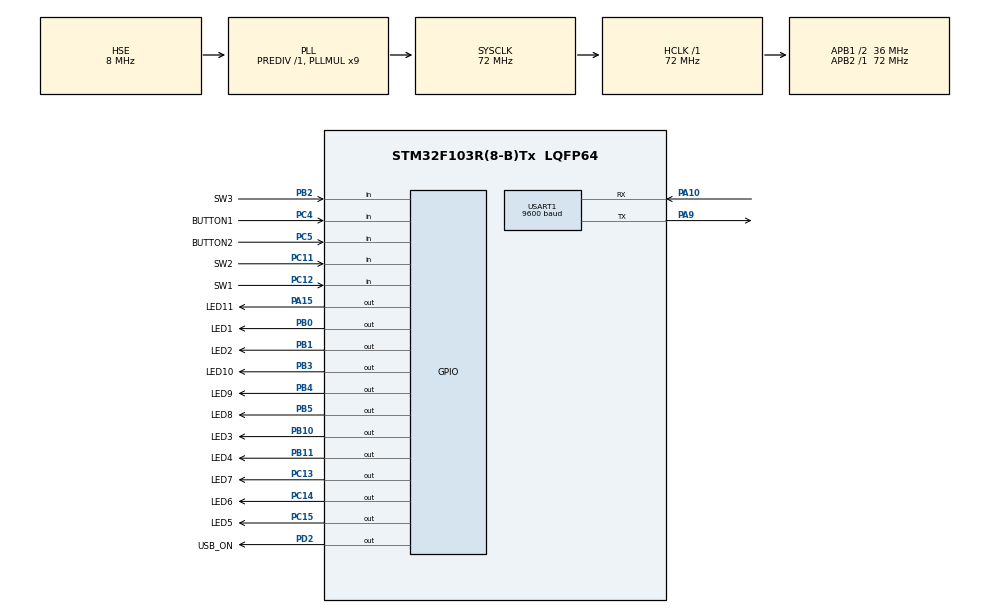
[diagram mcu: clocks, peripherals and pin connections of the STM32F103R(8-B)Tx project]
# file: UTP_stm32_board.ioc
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Mcu.Family=STM32F1
Mcu.Name=STM32F103R(8-B)Tx
Mcu.Package=LQFP64
NVIC.PriorityGroup=NVIC_PRIORITYGROUP_4
NVIC.USART1_IRQn=true\:0\:0\:false\:false\:true\:true
PA10.Mode=Asynchronous
PA10.Signal=USART1_RX
PA13.Mode=Serial_Wire
PA13.Signal=SYS_JTMS-SWDIO
PA14.Mode=Serial_Wire
PA14.Signal=SYS_JTCK-SWCLK
PA15.GPIO_Label=LED11
PA15.PinState=GPIO_PIN_SET
PA15.Signal=GPIO_Output
PA9.Mode=Asynchronous
PA9.Signal=USART1_TX
PB0.GPIO_Label=LED1
PB0.PinState=GPIO_PIN_SET
PB0.Signal=GPIO_Output
PB1.GPIO_Label=LED2
PB1.PinState=GPIO_PIN_SET
PB1.Signal=GPIO_Output
PB10.GPIO_Label=LED3
PB10.PinState=GPIO_PIN_SET
PB10.Signal=GPIO_Output
PB11.GPIO_Label=LED4
PB11.PinState=GPIO_PIN_SET
PB11.Signal=GPIO_Output
PB2.GPIO_Label=SW3
PB2.GPIO_PuPd=GPIO_PULLUP
PB2.Signal=GPIO_Input
PB3.GPIO_Label=LED10
PB3.PinState=GPIO_PIN_SET
PB3.Signal=GPIO_Output
PB4.GPIO_Label=LED9
PB4.PinState=GPIO_PIN_SET
PB4.Signal=GPIO_Output
PB5.GPIO_Label=LED8
PB5.PinState=GPIO_PIN_SET
PB5.Signal=GPIO_Output
PC11.GPIO_Label=SW2
PC11.GPIO_PuPd=GPIO_PULLUP
PC11.Signal=GPIO_Input
PC12.GPIO_Label=SW1
PC12.GPIO_PuPd=GPIO_PULLUP
PC12.Signal=GPIO_Input
PC13-TAMPER-RTC.GPIO_Label=LED7
PC13-TAMPER-RTC.PinState=GPIO_PIN_SET
PC13-TAMPER-RTC.Signal=GPIO_Output
PC14-OSC32_IN.GPIO_Label=LED6
PC14-OSC32_IN.PinState=GPIO_PIN_SET
PC14-OSC32_IN.Signal=GPIO_Output
PC15-OSC32_OUT.GPIO_Label=LED5
PC15-OSC32_OUT.PinState=GPIO_PIN_SET
PC15-OSC32_OUT.Signal=GPIO_Output
PC4.GPIO_Label=BUTTON1
PC4.GPIO_PuPd=GPIO_PULLUP
PC4.Signal=GPIO_Input
PC5.GPIO_Label=BUTTON2
PC5.GPIO_PuPd=GPIO_PULLUP
PC5.Signal=GPIO_Input
PD0-OSC_IN.Mode=HSE-External-Oscillator
PD0-OSC_IN.Signal=RCC_OSC_IN
PD1-OSC_OUT.Mode=HSE-External-Oscillator
PD1-OSC_OUT.Signal=RCC_OSC_OUT
PD2.GPIO_Label=USB_ON
PD2.PinState=GPIO_PIN_SET
PD2.Signal=GPIO_Output
ProjectManager.HeapSize=0x200
ProjectManager.StackSize=0x400
ProjectManager.TargetToolchain=TrueSTUDIO
RCC.ADCPresc=RCC_ADCPCLK2_DIV6
RCC.AHBFreq_Value=72000000
RCC.APB1CLKDivider=RCC_HCLK_DIV2
RCC.APB1Freq_Value=36000000
RCC.APB1TimFreq_Value=72000000
RCC.APB2Freq_Value=72000000
RCC.APB2TimFreq_Value=72000000
RCC.HCLKFreq_Value=72000000
RCC.PLLMUL=RCC_PLL_MUL9
RCC.PLLSourceVirtual=RCC_PLLSOURCE_HSE
RCC.SYSCLKFreq_VALUE=72000000
RCC.SYSCLKSource=RCC_SYSCLKSOURCE_PLLCLK
RCC.USBFreq_Value=48000000
RCC.USBPrescaler=RCC_USBCLKSOURCE_PLL_DIV1_5
USART1.BaudRate=9600
USART1.Parity=PARITY_ODD
USART1.StopBits=STOPBITS_2
USART1.VirtualMode=VM_ASYNC
board=UTP_stm32_board

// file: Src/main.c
/**
  ******************************************************************************
  * File Name          : main.c
  * Description        : Main program body
  ******************************************************************************
  ** This notice applies to any and all portions of this file
  * that are not between comment pairs USER CODE BEGIN and
  * USER CODE END. Other portions of this file, whether
  * inserted by the user or by software development tools
  * are owned by their respective copyright owners.
  *
  * COPYRIGHT(c) 2017 STMicroelectronics
  *
  * Redistribution and use in source and binary forms, with or without modification,
  * are permitted provided that the following conditions are met:
  *   1. Redistributions of source code must retain the above copyright notice,
  *      this list of conditions and the following disclaimer.
  *   2. Redistributions in binary form must reproduce the above copyright notice,
  *      this list of conditions and the following disclaimer in the documentation
  *      and/or other materials provided with the distribution.
  *   3. Neither the name of STMicroelectronics nor the names of its contributors
  *      may be used to endorse or promote products derived from this software
  *      without specific prior written permission.
  *
  * THIS SOFTWARE IS PROVIDED BY THE COPYRIGHT HOLDERS AND CONTRIBUTORS "AS IS"
  * AND ANY EXPRESS OR IMPLIED WARRANTIES, INCLUDING, BUT NOT LIMITED TO, THE
  * IMPLIED WARRANTIES OF MERCHANTABILITY AND FITNESS FOR A PARTICULAR PURPOSE ARE
  * DISCLAIMED. IN NO EVENT SHALL THE COPYRIGHT HOLDER OR CONTRIBUTORS BE LIABLE
  * FOR ANY DIRECT, INDIRECT, INCIDENTAL, SPECIAL, EXEMPLARY, OR CONSEQUENTIAL
  * DAMAGES (INCLUDING, BUT NOT LIMITED TO, PROCUREMENT OF SUBSTITUTE GOODS OR
  * SERVICES; LOSS OF USE, DATA, OR PROFITS; OR BUSINESS INTERRUPTION) HOWEVER
  * CAUSED AND ON ANY THEORY OF LIABILITY, WHETHER IN CONTRACT, STRICT LIABILITY,
  * OR TORT (INCLUDING NEGLIGENCE OR OTHERWISE) ARISING IN ANY WAY OUT OF THE USE
  * OF THIS SOFTWARE, EVEN IF ADVISED OF THE POSSIBILITY OF SUCH DAMAGE.
  *
  ******************************************************************************
  */
#include "main.h"
#include "stm32f1xx_hal.h"

UART_HandleTypeDef huart1;

/* USER CODE BEGIN PV */
/* Private variables ---------------------------------------------------------*/

/* USER CODE END PV */

void SystemClock_Config(void);
static void MX_GPIO_Init(void);
static void MX_USART1_UART_Init(void);

/* USER CODE BEGIN PFP */
/* Private function prototypes -----------------------------------------------*/

/* USER CODE END PFP */

int main(void)
{

  /* MCU Configuration----------------------------------------------------------*/

  /* Reset of all peripherals, Initializes the Flash interface and the Systick. */
  HAL_Init();

  /* Configure the system clock */
  SystemClock_Config();

  /* Initialize all configured peripherals */
  MX_GPIO_Init();
  MX_USART1_UART_Init();

  /* Infinite loop */
  while (1)
  {

  /* USER CODE BEGIN 3 */
	  //uint8_t Data[20];
	 // uint8_t size = sprintf(Data,"Wysyłamy\n");
	 // H//AL_UART_Transmit(&huart1,Data,size,200);
	  HAL_GPIO_TogglePin(LED10_GPIO_Port, LED10_Pin);
	  HAL_Delay(1000);
  }
  /* USER CODE END 3 */

}

/** System Clock Configuration
*/
void SystemClock_Config(void)
{

  RCC_OscInitTypeDef RCC_OscInitStruct;
  RCC_ClkInitTypeDef RCC_ClkInitStruct;

    /**Initializes the CPU, AHB and APB busses clocks
    */
  RCC_OscInitStruct.OscillatorType = RCC_OSCILLATORTYPE_HSE;
  RCC_OscInitStruct.HSEState = RCC_HSE_ON;
  RCC_OscInitStruct.HSEPredivValue = RCC_HSE_PREDIV_DIV1;
  RCC_OscInitStruct.HSIState = RCC_HSI_ON;
  RCC_OscInitStruct.PLL.PLLState = RCC_PLL_ON;
  RCC_OscInitStruct.PLL.PLLSource = RCC_PLLSOURCE_HSE;
  RCC_OscInitStruct.PLL.PLLMUL = RCC_PLL_MUL9;
  if (HAL_RCC_OscConfig(&RCC_OscInitStruct) != HAL_OK)
  {
    _Error_Handler(__FILE__, __LINE__);
  }

    /**Initializes the CPU, AHB and APB busses clocks
    */
  RCC_ClkInitStruct.ClockType = RCC_CLOCKTYPE_HCLK|RCC_CLOCKTYPE_SYSCLK
                              |RCC_CLOCKTYPE_PCLK1|RCC_CLOCKTYPE_PCLK2;
  RCC_ClkInitStruct.SYSCLKSource = RCC_SYSCLKSOURCE_PLLCLK;
  RCC_ClkInitStruct.AHBCLKDivider = RCC_SYSCLK_DIV1;
  RCC_ClkInitStruct.APB1CLKDivider = RCC_HCLK_DIV2;
  RCC_ClkInitStruct.APB2CLKDivider = RCC_HCLK_DIV1;

  if (HAL_RCC_ClockConfig(&RCC_ClkInitStruct, FLASH_LATENCY_2) != HAL_OK)
  {
    _Error_Handler(__FILE__, __LINE__);
  }

    /**Configure the Systick interrupt time
    */
  HAL_SYSTICK_Config(HAL_RCC_GetHCLKFreq()/1000);

    /**Configure the Systick
    */
  HAL_SYSTICK_CLKSourceConfig(SYSTICK_CLKSOURCE_HCLK);

  /* SysTick_IRQn interrupt configuration */
  HAL_NVIC_SetPriority(SysTick_IRQn, 0, 0);
}

/* USART1 init function */
static void MX_USART1_UART_Init(void)
{

  huart1.Instance = USART1;
  huart1.Init.BaudRate = 9600;
  huart1.Init.WordLength = UART_WORDLENGTH_8B;
  huart1.Init.StopBits = UART_STOPBITS_2;
  huart1.Init.Parity = UART_PARITY_ODD;
  huart1.Init.Mode = UART_MODE_TX_RX;
  huart1.Init.HwFlowCtl = UART_HWCONTROL_NONE;
  huart1.Init.OverSampling = UART_OVERSAMPLING_16;
  if (HAL_UART_Init(&huart1) != HAL_OK)
  {
    _Error_Handler(__FILE__, __LINE__);
  }

}

/** Configure pins as
        * Analog
        * Input
        * Output
        * EVENT_OUT
        * EXTI
*/
static void MX_GPIO_Init(void)
{

  GPIO_InitTypeDef GPIO_InitStruct;

  /* GPIO Ports Clock Enable */
  __HAL_RCC_GPIOC_CLK_ENABLE();
  __HAL_RCC_GPIOD_CLK_ENABLE();
  __HAL_RCC_GPIOB_CLK_ENABLE();
  __HAL_RCC_GPIOA_CLK_ENABLE();

  /*Configure GPIO pin Output Level */
  HAL_GPIO_WritePin(GPIOC, LED7_Pin|LED6_Pin|LED5_Pin, GPIO_PIN_SET);

  /*Configure GPIO pin Output Level */
  HAL_GPIO_WritePin(GPIOB, LED1_Pin|LED2_Pin|LED3_Pin|LED4_Pin
                          |LED10_Pin|LED9_Pin|LED8_Pin, GPIO_PIN_SET);

  /*Configure GPIO pin Output Level */
  HAL_GPIO_WritePin(LED11_GPIO_Port, LED11_Pin, GPIO_PIN_SET);

  /*Configure GPIO pin Output Level */
  HAL_GPIO_WritePin(USB_ON_GPIO_Port, USB_ON_Pin, GPIO_PIN_SET);

  /*Configure GPIO pins : LED7_Pin LED6_Pin LED5_Pin */
  GPIO_InitStruct.Pin = LED7_Pin|LED6_Pin|LED5_Pin;
  GPIO_InitStruct.Mode = GPIO_MODE_OUTPUT_PP;
  GPIO_InitStruct.Speed = GPIO_SPEED_FREQ_LOW;
  HAL_GPIO_Init(GPIOC, &GPIO_InitStruct);

  /*Configure GPIO pins : BUTTON1_Pin BUTTON2_Pin SW2_Pin SW1_Pin */
  GPIO_InitStruct.Pin = BUTTON1_Pin|BUTTON2_Pin|SW2_Pin|SW1_Pin;
  GPIO_InitStruct.Mode = GPIO_MODE_INPUT;
  GPIO_InitStruct.Pull = GPIO_PULLUP;
  HAL_GPIO_Init(GPIOC, &GPIO_InitStruct);

  /*Configure GPIO pins : LED1_Pin LED2_Pin LED3_Pin LED4_Pin
                           LED10_Pin LED9_Pin LED8_Pin */
  GPIO_InitStruct.Pin = LED1_Pin|LED2_Pin|LED3_Pin|LED4_Pin
                          |LED10_Pin|LED9_Pin|LED8_Pin;
  GPIO_InitStruct.Mode = GPIO_MODE_OUTPUT_PP;
  GPIO_InitStruct.Speed = GPIO_SPEED_FREQ_LOW;
  HAL_GPIO_Init(GPIOB, &GPIO_InitStruct);

  /*Configure GPIO pin : SW3_Pin */
  GPIO_InitStruct.Pin = SW3_Pin;
  GPIO_InitStruct.Mode = GPIO_MODE_INPUT;
  GPIO_InitStruct.Pull = GPIO_PULLUP;
  HAL_GPIO_Init(SW3_GPIO_Port, &GPIO_InitStruct);

  /*Configure GPIO pin : LED11_Pin */
  GPIO_InitStruct.Pin = LED11_Pin;
  GPIO_InitStruct.Mode = GPIO_MODE_OUTPUT_PP;
  GPIO_InitStruct.Speed = GPIO_SPEED_FREQ_LOW;
  HAL_GPIO_Init(LED11_GPIO_Port, &GPIO_InitStruct);

  /*Configure GPIO pin : USB_ON_Pin */
  GPIO_InitStruct.Pin = USB_ON_Pin;
  GPIO_InitStruct.Mode = GPIO_MODE_OUTPUT_PP;
  GPIO_InitStruct.Speed = GPIO_SPEED_FREQ_LOW;
  HAL_GPIO_Init(USB_ON_GPIO_Port, &GPIO_InitStruct);

}

void _Error_Handler(char * file, int line)
{
  while(1)
  {
  }
}

/************************ (C) COPYRIGHT STMicroelectronics *****END OF FILE****/
